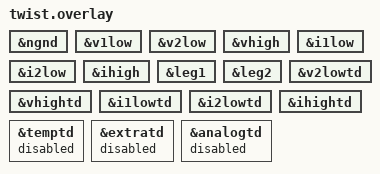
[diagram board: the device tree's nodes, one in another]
/*
 * Copyright (c) 2023-2024 OwnTech.
 *
 * SPDX-License-Identifier: LGPL-2.1
 */

#include "can-standby-switch.dtsi"
#include "sensors.dtsi"
#include "ngnd.dtsi"
#include "pwm_legs.dtsi"
#include "safety-thresholds.dtsi"

&ngnd {
	status = "okay";
};

&v1low {
	status = "okay";
};

&v2low {
	status = "okay";
};

&vhigh {
	status = "okay";
};

&i1low {
	status = "okay";
};

&i2low {
	status = "okay";
};

&ihigh {
	status = "okay";
};


&leg1 {
	status = "okay";
};

&leg2 {
	status = "okay";
};

&v2lowtd{
	status = "okay";
};

&vhightd{
	status = "okay";
};

&i1lowtd{
	status = "okay";
};

&i2lowtd{
	status = "okay";
};

&ihightd{
	status = "okay";
};

&temptd{
	status = "disabled";
};

&extratd{
	status = "disabled";
};

&analogtd{
	status = "disabled";
};
